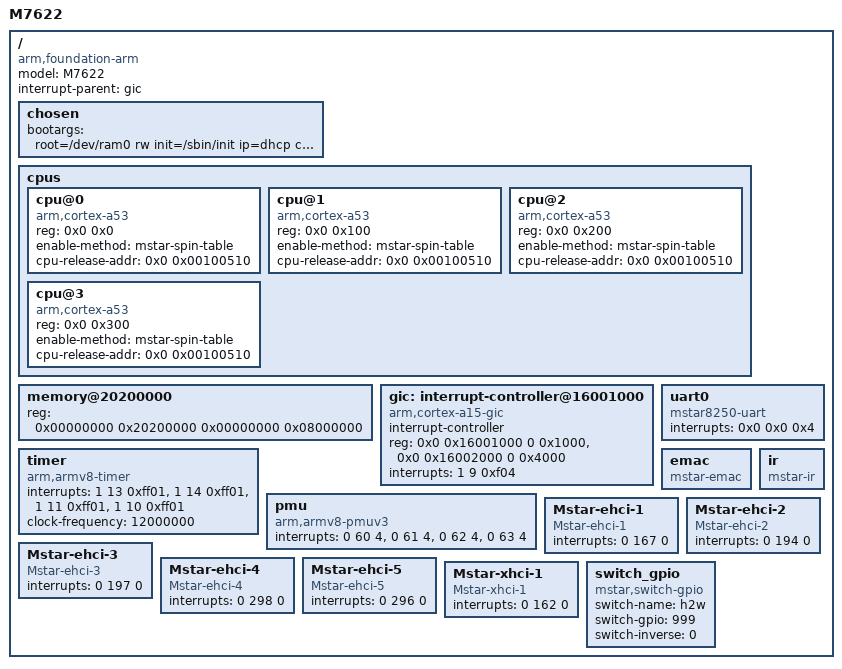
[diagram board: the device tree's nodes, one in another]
/*
 * ARM Ltd.
 *
 * ARMv8 Foundation model DTS
 */

/dts-v1/;
/ {
	model = "M7622";
	compatible = "arm,foundation-arm", "arm,m7622";
	interrupt-parent = <&gic>;
	#address-cells = <2>;
	#size-cells = <2>;

    /* rdinit=/sbin/init */
	chosen {
         bootargs = "root=/dev/ram0 rw init=/sbin/init ip=dhcp console=ttyS0,38400,LX_MEM=0x03000000";
        };

	cpus {
		#address-cells = <2>;
		#size-cells = <0>;

		cpu@0 {
			device_type = "cpu";
			compatible = "arm,cortex-a53", "arm,armv8";
			reg = <0x0 0x0>;
			enable-method = "mstar-spin-table";
			cpu-release-addr = <0x0 0x00100510>;
		};

		cpu@1 {
			device_type = "cpu";
			compatible = "arm,cortex-a53", "arm,armv8";
			reg = <0x0 0x100>;
			enable-method = "mstar-spin-table";
			cpu-release-addr = <0x0 0x00100510>;
		};
	
		cpu@2 {
			device_type = "cpu";
			compatible = "arm,cortex-a53", "arm,armv8";
			reg = <0x0 0x200>;
			enable-method = "mstar-spin-table";
			cpu-release-addr = <0x0 0x00100510>;
		};
		
		cpu@3 {
			device_type = "cpu";
			compatible = "arm,cortex-a53", "arm,armv8";
			reg = <0x0 0x300>;
			enable-method = "mstar-spin-table";
			cpu-release-addr = <0x0 0x00100510>;
		};
	};

	memory@20200000 {
		device_type = "memory";
		reg = <0x00000000 0x20200000 0x00000000 0x08000000>;
	};

	gic: interrupt-controller@16001000 {
		compatible = "arm,cortex-a15-gic", "arm,cortex-a9-gic";
		#interrupt-cells = <3>;
		#address-cells = <0>;
		interrupt-controller;
		reg = <0x0 0x16001000 0 0x1000>,
		      <0x0 0x16002000 0 0x4000>;
		interrupts = <1 9 0xf04>;
	};

	uart0 {
		compatible = "mstar8250-uart";
		interrupts = <0x0 0x0 0x4>;
	};

	timer {
		compatible = "arm,armv8-timer";
		interrupts = <1 13 0xff01>,
			     <1 14 0xff01>,
			     <1 11 0xff01>,
			     <1 10 0xff01>;
		clock-frequency = <12000000>;
	};

	pmu {
		compatible = "arm,armv8-pmuv3";
		interrupts = <0 60 4>,
			     <0 61 4>,
			     <0 62 4>,
			     <0 63 4>;
	};

	emac {
	        compatible = "mstar-emac";
	};

	ir {
	        compatible = "mstar-ir";
	};

	Mstar-ehci-1 {
		compatible = "Mstar-ehci-1";
		/* UHC1 int : 199 */
		interrupts = <0 167 0>;
	};

	Mstar-ehci-2 {
		compatible = "Mstar-ehci-2";
		/* UHC2 int : 226 */
		interrupts = <0 194 0>;
	};

	Mstar-ehci-3 {
		compatible = "Mstar-ehci-3";
		/* UHC3 int : 229 */
		interrupts = <0 197 0>;
	};

	 Mstar-ehci-4 {
	        compatible = "Mstar-ehci-4";
	        // UHC4 int : 330
	        interrupts = <0 298 0>;
	  };

	  Mstar-ehci-5 {
	        compatible = "Mstar-ehci-5";
	        // UHC5 int : 328
	        interrupts = <0 296 0>;
	  };


	Mstar-xhci-1 {
		compatible = "Mstar-xhci-1";
		/* XHC1 int : 194 */
		interrupts = <0 162 0>;
	};

	switch_gpio {
		compatible = "mstar,switch-gpio";
		switch-name = "h2w";
		switch-gpio = <999>;
		switch-inverse = <0>;
	};
};
